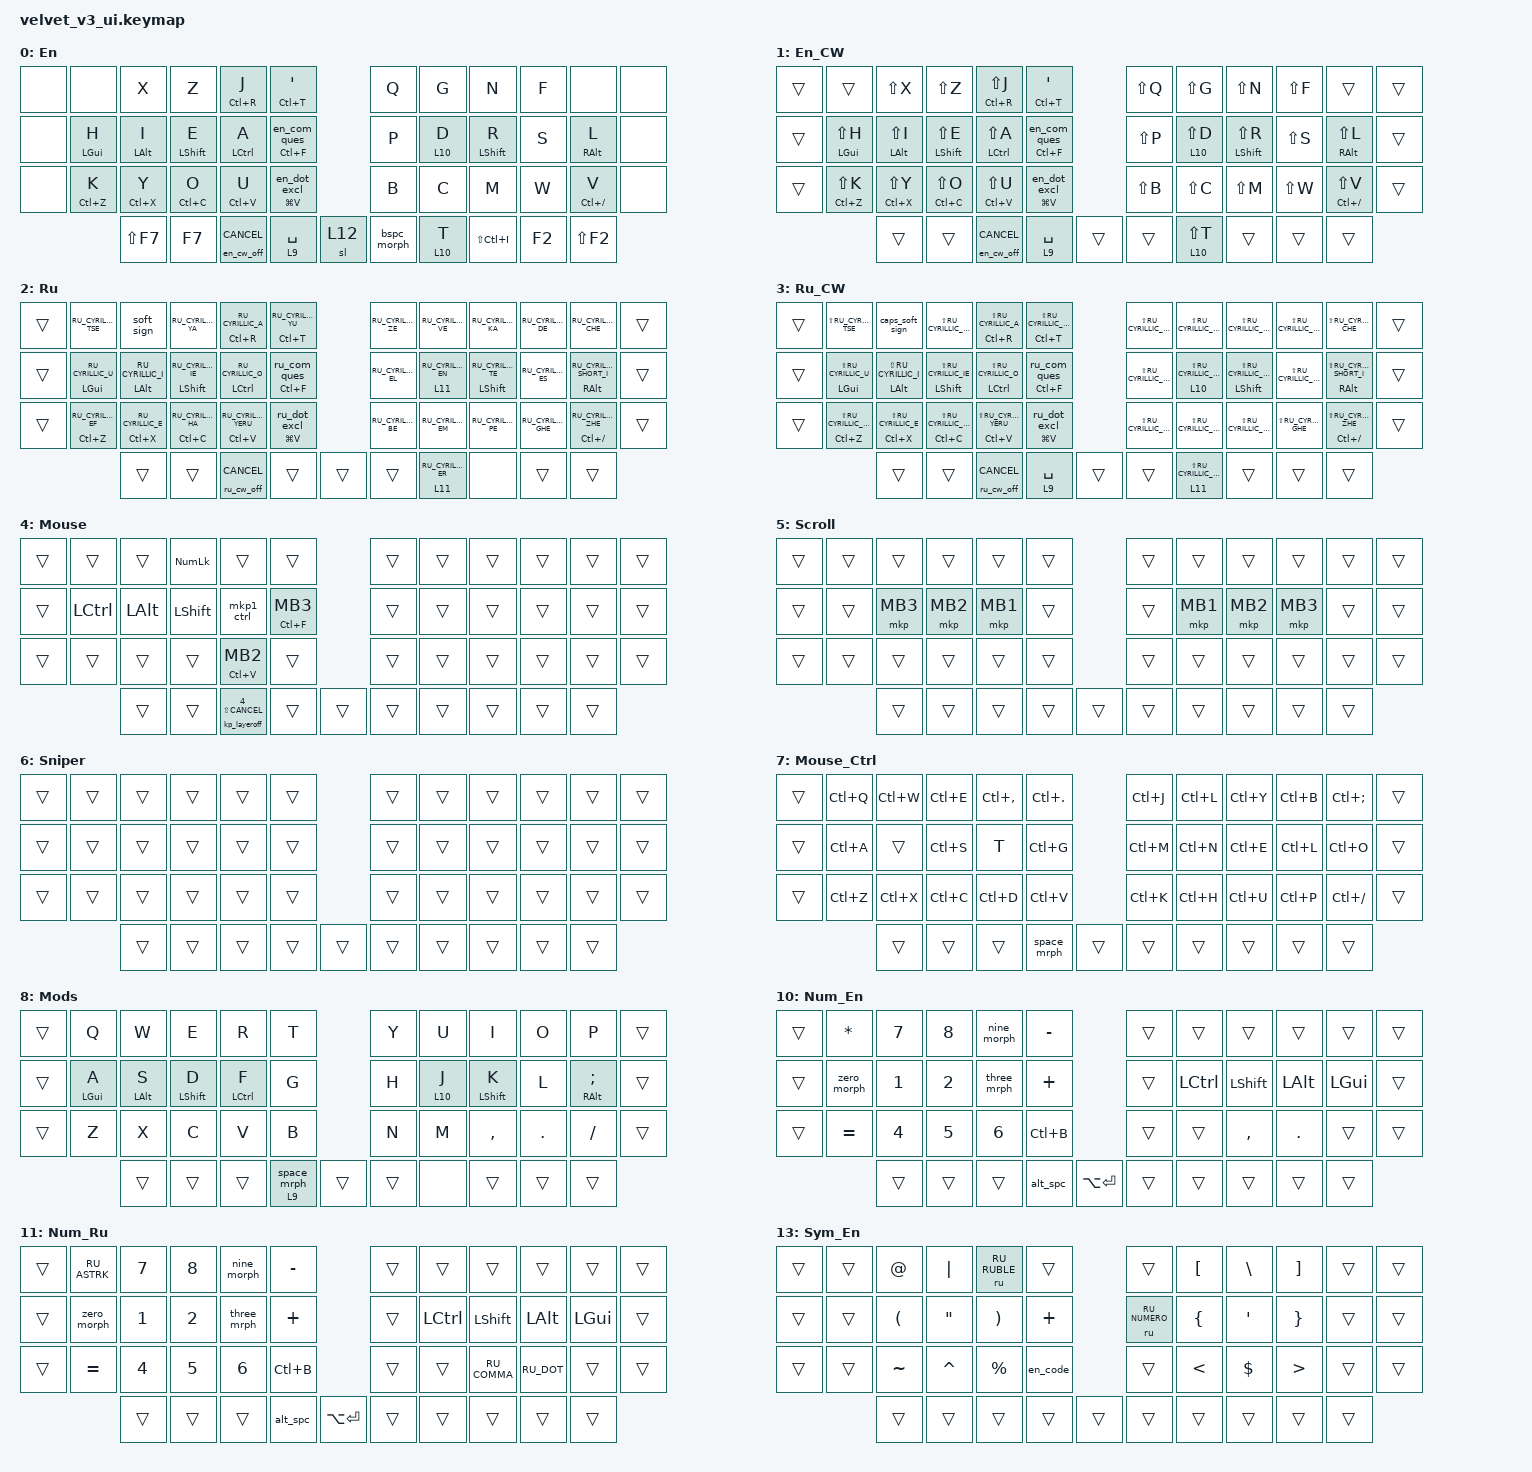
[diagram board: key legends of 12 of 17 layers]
#include "keys_ru.h"
#include <dt-bindings/zmk/input_transform.h>
#include <input/processors.dtsi>
#include <zephyr/dt-bindings/input/input-event-codes.h>
#include <dt-bindings/zmk/behaviors.h>
#include <behaviors.dtsi>
#include <dt-bindings/zmk/bt.h>
#include <dt-bindings/zmk/keys.h>
#include <dt-bindings/zmk/outputs.h>
#include <dt-bindings/zmk/pointing.h>

&mt {
    flavor = "tap-preferred";
    tapping-term-ms = <200>;
    bindings = <&kp_>, <&kp>;
};

&lt { flavor = "balanced"; };

&sl {
    release-after-ms = <5000>;
    ignore-modifiers;
};

&sk {
    release-after-ms = <5000>;
    quick-release;
};

&key_repeat { usage-pages = <HID_USAGE_KEY HID_USAGE_CONSUMER>; };

/ {
    combos {
        compatible = "zmk,combos";

        combo_ctrl_ent {
            bindings = <&kp LC(ENTER)>;
            key-positions = <2 4>;
            require-prior-idle-ms = <30>;
        };

        combo_enter {
            bindings = <&kp ENTER>;
            key-positions = <3 2>;
            require-prior-idle-ms = <30>;
            timeout-ms = <30>;
        };

        combo_tab {
            bindings = <&kp TAB>;
            key-positions = <14 15>;
            require-prior-idle-ms = <30>;
            timeout-ms = <30>;
        };

        combo_esc {
            bindings = <&kp ESC>;
            key-positions = <26 27>;
            require-prior-idle-ms = <30>;
            timeout-ms = <30>;
        };

        combo_ru {
            bindings = <&layer_ru>;
            key-positions = <27 28>;
            timeout-ms = <30>;
            require-prior-idle-ms = <(-1)>;
        };

        combo_en {
            bindings = <&layer_en>;
            key-positions = <31 32>;
            timeout-ms = <30>;
            require-prior-idle-ms = <(-1)>;
        };

        combo_osl_sym_en {
            bindings = <&sl 13>;
            key-positions = <19 20>;
            require-prior-idle-ms = <50>;
            layers = <0 1 13>;
        };

        combo_quotes_en {
            bindings = <&quotes_en>;
            require-prior-idle-ms = <30>;
            key-positions = <31 33>;
            layers = <0 1 13>;
        };

        combo_osl_sym_ru {
            bindings = <&sl 14>;
            key-positions = <19 20>;
            require-prior-idle-ms = <50>;
            layers = <2 3 14>;
        };

        combo_quotes_ru {
            bindings = <&quotes_ru>;
            key-positions = <31 33>;
            require-prior-idle-ms = <30>;
            layers = <2 3>;
        };

        combo_braces_en {
            bindings = <&braces_en>;
            key-positions = <19 21>;
            require-prior-idle-ms = <50>;
            layers = <0 1 13>;
        };

        cmb_bcsp {
            bindings = <&none>;
            timeout-ms = <30>;
            key-positions = <20 21>;
            require-prior-idle-ms = <15>;
            layers = <16>;
        };

        combo_she_ru {
            bindings = <&kp RU_CYRILLIC_SHA>;
            timeout-ms = <30>;
            key-positions = <32 33>;
            require-prior-idle-ms = <15>;
            layers = <2>;
        };

        combo_scha_ru {
            bindings = <&kp RU_CYRILLIC_SHCHA>;
            timeout-ms = <30>;
            key-positions = <8 9>;
            require-prior-idle-ms = <15>;
            layers = <2>;
        };

        combo_she_cw {
            bindings = <&kp LS(RU_CYRILLIC_SHA)>;
            timeout-ms = <30>;
            key-positions = <32 33>;
            layers = <3>;
            require-prior-idle-ms = <15>;
        };

        combo_scha_cw {
            bindings = <&kp LS(RU_CYRILLIC_SHCHA)>;
            timeout-ms = <30>;
            key-positions = <8 9>;
            layers = <3>;
            require-prior-idle-ms = <15>;
        };

        combo_capsword_en {
            bindings = <&to 1>;
            key-positions = <14 13>;
            layers = <0 1>;
        };

        combo_osl_fn {
            bindings = <&sl 15>;
            key-positions = <26 28>;
        };

        combo_osl_os {
            bindings = <&sl 16>;
            key-positions = <25 26>;
        };

        combo_capsword_ru {
            bindings = <&to 3>;
            key-positions = <14 13>;
            layers = <2 3>;
        };

        combo_yo_ru {
            bindings = <&kp RU_CYRILLIC_IO>;
            key-positions = <21 22>;
            layers = <2>;
        };

        combo_yo_cw_ru {
            bindings = <&kp LS(RU_CYRILLIC_IO)>;
            key-positions = <21 22>;
            layers = <3>;
        };

        combo_yo_en {
            bindings = <&ru RU_CYRILLIC_IO>;
            key-positions = <21 22>;
            layers = <0>;
        };

        parentheses {
            bindings = <&parentheses>;
            key-positions = <14 16>;
            timeout-ms = <30>;
            require-prior-idle-ms = <50>;
        };

        combo_braces_ru {
            bindings = <&braces_ru>;
            key-positions = <19 21>;
            timeout-ms = <25>;
            layers = <2 3 14>;
            require-prior-idle-ms = <50>;
        };

        combo_brackets_en {
            bindings = <&brackets_en>;
            key-positions = <7 9>;
            layers = <0 1 13>;
            timeout-ms = <30>;
            require-prior-idle-ms = <30>;
        };

        combo_brackets_ru {
            bindings = <&brackets_ru>;
            key-positions = <7 9>;
            layers = <2 3 14>;
            timeout-ms = <30>;
        };

        combo_minus {
            bindings = <&kp MINUS>;
            key-positions = <3 4>;
            require-prior-idle-ms = <30>;
            timeout-ms = <30>;
        };

        combo_grave_ru {
            bindings = <&ru_grave>;
            key-positions = <19 18>;
            layers = <2 3 14>;
        };

        combo_grave_en {
            bindings = <&en_grave>;
            key-positions = <19 18>;
            layers = <0 1 13>;
        };

        combo_under_en {
            bindings = <&kp UNDER>;
            key-positions = <7 8>;
            require-prior-idle-ms = <30>;
            timeout-ms = <30>;
        };

        combo_ru_hash {
            bindings = <&en HASH>;
            key-positions = <30 31>;
            layers = <2 3 14>;
        };

        combo_en_hash {
            bindings = <&kp HASH>;
            key-positions = <30 31>;
            layers = <0 1 13>;
        };

        combo_en_slash {
            bindings = <&kp SLASH>;
            key-positions = <16 17>;
            layers = <0 1 10 13>;
        };

        combo_ru_slash {
            bindings = <&en SLASH>;
            key-positions = <16 17>;
            layers = <2 3 14 11>;
        };

        combo_en_amp {
            bindings = <&kp AMPS>;
            key-positions = <28 29>;
            layers = <0 1 10 13>;
        };

        combo_en_semi {
            bindings = <&kp SEMI>;
            key-positions = <4 5>;
            layers = <0 1 10 13>;
        };

        combo_ru_semi {
            bindings = <&kp RU_SEMI>;
            key-positions = <4 5>;
            layers = <2 3 11 14>;
        };

        combo_ru_amp {
            bindings = <&en AMPS>;
            key-positions = <28 29>;
            layers = <2 3 11 14>;
        };

        combo_en_colon {
            bindings = <&kp COLON>;
            key-positions = <6 7>;
            layers = <0 1 10 13>;
        };

        combo_ru_colon {
            bindings = <&kp RU_COLON>;
            key-positions = <6 7>;
            layers = <2 3 10 13>;
        };
    };

    macros {
        layer_ru: lg_ru {
            compatible = "zmk,behavior-macro";
            #binding-cells = <0>;
            bindings = <&to 2 &kp LS(LC(N8))>;
            label = "LG_RU";
            tap-ms = <40>;
            wait-ms = <0>;
        };

        layer_en: lg_en {
            compatible = "zmk,behavior-macro";
            #binding-cells = <0>;
            bindings = <&to 0 &kp LS(LC(N9))>;
            label = "LG_EN";
            tap-ms = <40>;
            wait-ms = <0>;
        };

        to_ru: to_ru {
            compatible = "zmk,behavior-macro";
            #binding-cells = <0>;
            bindings = <&kp LC(LS(N8))>;
            label = "TO_RU";
            tap-ms = <40>;
            wait-ms = <0>;
        };

        to_en: to_en {
            compatible = "zmk,behavior-macro";
            #binding-cells = <0>;
            bindings = <&kp LC(LS(N9))>;
            label = "TO_EN";
            wait-ms = <0>;
            tap-ms = <40>;
        };

        en: en {
            compatible = "zmk,behavior-macro-one-param";
            #binding-cells = <1>;
            bindings = <&kp LC(LS(N9)) &macro_param_1to1 &kp MACRO_PLACEHOLDER &kp LC(LS(N8))>;
            label = "EN";
            wait-ms = <10>;
            tap-ms = <40>;
        };

        ru: ru {
            compatible = "zmk,behavior-macro-one-param";
            #binding-cells = <1>;
            bindings = <&kp LC(LS(N8)) &macro_param_1to1 &kp MACRO_PLACEHOLDER &kp LS(LC(N9))>;
            label = "RU";
            tap-ms = <40>;
        };

        alt_tab: alt_tab {
            compatible = "zmk,behavior-macro";
            #binding-cells = <0>;
            bindings =
                <&macro_wait_time 30>,
                <&macro_press>,
                <&kp LEFT_ALT>,
                <&macro_tap>,
                <&kp TAB>,
                <&macro_release>,
                <&kp LEFT_ALT>;

            label = "ALT_TAB";
            tap-ms = <30>;
        };

        select_row: select_row {
            compatible = "zmk,behavior-macro";
            #binding-cells = <0>;
            bindings = <&kp END &kp LS(HOME)>;
            label = "SELECT_ROW";
            wait-ms = <0>;
        };

        en_code: en_code_block {
            compatible = "zmk,behavior-macro";
            #binding-cells = <0>;
            bindings =
                <&macro_wait_time 10>,
                <&kp GRAVE &kp GRAVE &kp GRAVE &kp RETURN &kp RET &kp GRAVE &kp GRAVE &kp GRAVE &kp UP_ARROW>;

            label = "EN_CODE_BLOCK";
        };

        ru_code: ru_code {
            compatible = "zmk,behavior-macro";
            #binding-cells = <0>;
            bindings = <&kp LS(LC(N9)) &kp GRAVE &kp GRAVE &kp GRAVE &kp RETURN &kp RET &kp GRAVE &kp GRAVE &kp GRAVE &kp UP_ARROW &kp LC(LS(N8))>;
            label = "RU_CODE";
            tap-ms = <30>;
        };

        ru_cw_off: ru_cw_off {
            compatible = "zmk,behavior-macro-one-param";
            #binding-cells = <1>;
            bindings = <&macro_param_1to1 &kp MACRO_PLACEHOLDER &to 2>;
            label = "RU_CW_OFF";
            wait-ms = <0>;
        };

        en_cw_off: en_cw_off {
            compatible = "zmk,behavior-macro-one-param";
            #binding-cells = <1>;
            bindings = <&macro_param_1to1 &kp MACRO_PLACEHOLDER &to 0>;
            label = "EN_CW_OFF";
            wait-ms = <0>;
        };

        zeros_macro: zeros_macro {
            compatible = "zmk,behavior-macro";
            #binding-cells = <0>;
            bindings = <&kp N0 &kp N0 &kp N0 &kp N0 &kp N0 &kp N0>;
            label = "ZEROS_MACRO";
            tap-ms = <200>;
        };

        osm_ctrl_shift: osm_ctrl_shift {
            compatible = "zmk,behavior-macro";
            #binding-cells = <0>;
            bindings = <&sk LS(LCTRL) &sl 8>;
            label = "OSM_CTRL_SHIFT";
            wait-ms = <0>;
            tap-ms = <0>;
        };

        ml: ml {
            compatible = "zmk,behavior-macro-one-param";
            #binding-cells = <1>;
            bindings =
                <&macro_param_1to1 &key_on MACRO_PLACEHOLDER &layer_on 8>,
                <&macro_pause_for_release>,
                <&macro_param_1to1 &key_off MACRO_PLACEHOLDER &layer_off 8>;

            label = "Mod Layer";
            wait-ms = <0>;
            tap-ms = <0>;
        };

        quotes_ru: dbl_quote {
            compatible = "zmk,behavior-macro";
            #binding-cells = <0>;
            bindings = <&kp LS(NUMBER_2) &kp LS(NUMBER_2) &kp LEFT_ARROW>;
            label = "DBL_QUOTE";
            wait-ms = <0>;
        };

        quotes_en: quotes_en {
            compatible = "zmk,behavior-macro";
            #binding-cells = <0>;
            bindings = <&kp DOUBLE_QUOTES &kp DOUBLE_QUOTES &kp LEFT_ARROW>;
            label = "QUOTES_EN";
            wait-ms = <0>;
        };

        braces_en: braces_en {
            compatible = "zmk,behavior-macro";
            #binding-cells = <0>;
            bindings = <&kp LEFT_BRACE &kp RIGHT_BRACE &kp LEFT>;
            label = "BRACES_EN";
            wait-ms = <0>;
        };

        braces_ru: braces_ru {
            compatible = "zmk,behavior-macro";
            #binding-cells = <0>;
            bindings = <&to_en &braces_en &to_ru>;
            label = "BRACES_RU";
            wait-ms = <0>;
            tap-ms = <40>;
        };

        brackets_en: brackets_en {
            compatible = "zmk,behavior-macro";
            #binding-cells = <0>;
            bindings = <&kp LEFT_BRACKET &kp RIGHT_BRACKET &kp LEFT_ARROW>;
            label = "BRACKETS_EN";
            wait-ms = <0>;
        };

        brackets_ru: brackets_ru {
            compatible = "zmk,behavior-macro";
            #binding-cells = <0>;
            bindings = <&to_en &brackets_en &to_ru>;
            label = "BRACKETS_RU";
            wait-ms = <20>;
            tap-ms = <40>;
        };

        parentheses: parentheses {
            compatible = "zmk,behavior-macro";
            #binding-cells = <0>;
            bindings = <&kp LEFT_PARENTHESIS &kp RIGHT_PARENTHESIS &kp LEFT_ARROW>;
            label = "PARENTHESES";
            wait-ms = <0>;
        };

        less_greater_en: less_greater_en {
            compatible = "zmk,behavior-macro";
            #binding-cells = <0>;
            bindings = <&kp LESS_THAN &kp GREATER_THAN &kp LEFT>;
            label = "LESS_GREATER_EN";
            wait-ms = <0>;
        };

        less_greater_ru: less_greater_ru {
            compatible = "zmk,behavior-macro";
            #binding-cells = <0>;
            bindings = <&kp LS(LC(N9)) &less_greater_en &kp LS(LC(N8))>;
            label = "LESS_GREATER_RU";
        };

        osm_ctrl: osm_ctrl {
            compatible = "zmk,behavior-macro";
            #binding-cells = <0>;
            bindings = <&sk LCTRL &sl 8>;
            label = "OSM_CTRL";
            wait-ms = <0>;
            tap-ms = <0>;
        };

        sync_lg: sync_lg {
            compatible = "zmk,behavior-macro";
            #binding-cells = <0>;
            bindings = <&tog 2>;
            label = "SYNC_LG";
        };

        alt_spc: alt_spc {
            compatible = "zmk,behavior-macro";
            #binding-cells = <0>;
            bindings = <&kp LA(SPACE) &layer_off 4>;
            label = "ALT_SPC";
            wait-ms = <0>;
            tap-ms = <0>;
        };

        bspc_msoff: bspc_msoff {
            compatible = "zmk,behavior-macro";
            #binding-cells = <0>;
            bindings = <&layer_off 4 &bspc_morph>;
            label = "BSPC_MSOFF";
            tap-ms = <0>;
            wait-ms = <0>;
        };

        trns_msoff: trns_msoff {
            compatible = "zmk,behavior-macro";
            #binding-cells = <0>;
            bindings =
                <&macro_press>,
                <&trans>,
                <&macro_pause_for_release>,
                <&macro_release>,
                <&trans>,
                <&macro_tap>,
                <&layer_off 4>;

            label = "TRNS_MSOFF";
            wait-ms = <0>;
            tap-ms = <0>;
        };

        kp_msoff: kp_msoff {
            compatible = "zmk,behavior-macro-one-param";
            #binding-cells = <1>;
            bindings =
                <&macro_tap>,
                <&layer_off 4>,
                <&macro_press>,
                <&macro_param_1to1 &kp MACRO_PLACEHOLDER>,
                <&macro_pause_for_release>,
                <&macro_release>,
                <&macro_param_1to1 &kp MACRO_PLACEHOLDER>;

            label = "KP_MSOFF";
            wait-ms = <0>;
            tap-ms = <0>;
        };

        kp_layeroff: cancel_msoff {
            compatible = "zmk,behavior-macro-two-param";
            #binding-cells = <2>;
            bindings = <&macro_param_1to1 &layer_off MACRO_PLACEHOLDER &macro_param_2to1 &kp MACRO_PLACEHOLDER>;
            label = "CANCEL_MSOFF";
        };

        mkp1_ctrl: mkp1_ctrl {
            compatible = "zmk,behavior-macro";
            #binding-cells = <0>;
            bindings =
                <&macro_press>,
                <&mkp MB1 &mo 7 &kp LCTRL>,
                <&macro_pause_for_release>,
                <&macro_release>,
                <&mo 7>,
                <&macro_wait_time 50>,
                <&kp LCTRL &mkp MB1>;

            label = "MKP1_CTRL";
            wait-ms = <0>;
            tap-ms = <0>;
        };

        dkp: dkp {
            compatible = "zmk,behavior-macro-two-param";
            #binding-cells = <2>;
            bindings =
                <&macro_press>,
                <&macro_param_1to1 &kp MACRO_PLACEHOLDER &macro_param_2to1 &kp MACRO_PLACEHOLDER>,
                <&macro_pause_for_release>,
                <&macro_release>,
                <&macro_param_1to1 &kp MACRO_PLACEHOLDER &macro_param_2to1 &kp MACRO_PLACEHOLDER>;

            label = "DKP";
            wait-ms = <0>;
            tap-ms = <0>;
        };

        osm_shift: osm_shift {
            compatible = "zmk,behavior-macro";
            #binding-cells = <0>;
            bindings = <&sk LEFT_SHIFT &sl 8>;
            label = "OSM_SHIFT";
            wait-ms = <0>;
            tap-ms = <0>;
        };

        dbl_tap: dbl_tap {
            compatible = "zmk,behavior-macro-one-param";
            #binding-cells = <1>;
            bindings = <&macro_param_1to1 &kp MACRO_PLACEHOLDER &macro_param_1to1 &kp MACRO_PLACEHOLDER>;
            label = "DBL_TAP";
            tap-ms = <50>;
            wait-ms = <20>;
        };

        select_word: select_word {
            compatible = "zmk,behavior-macro";
            #binding-cells = <0>;
            bindings = <&kp LC(LEFT) &kp LC(LS(RIGHT))>;
            label = "SELECT_WORD";
        };

        kp_: kp_ {
            compatible = "zmk,behavior-macro-one-param";
            #binding-cells = <1>;
            bindings =
                <&macro_press>,
                <&macro_param_1to1 &kp MACRO_PLACEHOLDER>,
                <&macro_pause_for_release>,
                <&macro_release>,
                <&macro_param_1to1 &kp MACRO_PLACEHOLDER>;

            label = "KP_";
        };

        multi_kp: multi_kp {
            compatible = "zmk,behavior-macro-one-param";
            #binding-cells = <1>;
            bindings = <&macro_param_1to1 &kp MACRO_PLACEHOLDER &macro_param_1to1 &kp MACRO_PLACEHOLDER>;
            label = "MULTI_KP";
            tap-ms = <200>;
        };

        dbl_grave_ru: dbl_grave_ru {
            compatible = "zmk,behavior-macro";
            #binding-cells = <0>;
            bindings = <&kp LS(LC(N9)) &kp GRAVE &kp GRAVE &kp LEFT_ARROW &kp LS(LC(N8))>;
            label = "DBL_GRAVE_RU";
            wait-ms = <0>;
            tap-ms = <30>;
        };

        dbl_grave_en: dbl_grave_en {
            compatible = "zmk,behavior-macro";
            #binding-cells = <0>;
            bindings = <&kp GRAVE &kp GRAVE &kp LEFT_ARROW>;
            label = "DBL_GRAVE_EN";
            wait-ms = <0>;
            tap-ms = <30>;
        };

        triple_press: triple_press {
            compatible = "zmk,behavior-macro-one-param";
            #binding-cells = <1>;
            bindings = <&macro_param_1to1 &kp MACRO_PLACEHOLDER &macro_param_1to1 &kp MACRO_PLACEHOLDER &macro_param_1to1 &kp MACRO_PLACEHOLDER>;
            label = "TRIPLE_PRESS";
        };

        triple_press_en: triple_press_en {
            compatible = "zmk,behavior-macro-one-param";
            #binding-cells = <1>;
            bindings = <&kp N9 &macro_param_1to1 &kp MACRO_PLACEHOLDER &macro_param_1to1 &kp MACRO_PLACEHOLDER &macro_param_1to1 &kp MACRO_PLACEHOLDER &kp LS(LC(N8))>;
            label = "TRIPLE_PRESS_EN";
        };

        testops: testops {
            compatible = "zmk,behavior-macro";
            #binding-cells = <0>;
            bindings = <&kp LS(LC(LG(F7))) &kp LS(LC(LG(F8)))>;
            label = "TESTOPS";
            wait-ms = <500>;
            tap-ms = <150>;
        };
    };

    behaviors {
        en_magic: en_magic {
            compatible = "zmk,behavior-antecedent-morph";
            label = "EN_MAGIC";
            #binding-cells = <0>;
            defaults = <&none>;
            bindings = <&kp C>, <&kp B>, <&kp O>, <&kp E>, <&kp E>, <&kp I>;

            antecedents = <S I Z Y U P>;
            max-delay-ms = <2000>;
        };

        ru_magic: ru_magic {
            compatible = "zmk,behavior-antecedent-morph";
            label = "RU_MAGIC";
            #binding-cells = <0>;
            defaults = <&none>;
            bindings = <&kp C>, <&kp O>;

            antecedents = <S Z>;
            max-delay-ms = <1500>;
        };

        layer_off: layer_off {
            compatible = "zmk,behavior-toggle-layer";
            label = "LAYER_OFF";
            #binding-cells = <1>;
            toggle-mode = "off";
        };

        hrm: hrm {
            compatible = "zmk,behavior-hold-tap";
            label = "Home Row Mod";
            bindings = <&kp>, <&kp>;

            #binding-cells = <2>;
            tapping-term-ms = <200>;
            flavor = "balanced";
        };

        hrm_slow: hrm_slow {
            compatible = "zmk,behavior-hold-tap";
            label = "HRM for slow fingers";
            bindings = <&kp>, <&kp>;

            #binding-cells = <2>;
            flavor = "tap-preferred";
            tapping-term-ms = <200>;
        };

        ru_lt_cw_off: ru_lt_cw_off {
            compatible = "zmk,behavior-hold-tap";
            label = "RU_LT_CW_OFF";
            bindings = <&mo>, <&ru_cw_off>;

            #binding-cells = <2>;
            tapping-term-ms = <180>;
            flavor = "balanced";
        };

        en_lt_cw_off: en_lt_cw_off {
            compatible = "zmk,behavior-hold-tap";
            label = "EN_LT_CW_OFF";
            bindings = <&mo>, <&en_cw_off>;

            #binding-cells = <2>;
            tapping-term-ms = <180>;
            flavor = "balanced";
        };

        hrl: hrl {
            compatible = "zmk,behavior-hold-tap";
            label = "Home Row Layer";
            bindings = <&mo>, <&kp>;

            #binding-cells = <2>;
            tapping-term-ms = <200>;
            flavor = "balanced";
        };

        lt_bspc: lt_bspc {
            compatible = "zmk,behavior-hold-tap";
            label = "LT with quick tap and mod morph";
            bindings = <&mo>, <&bspc_msoff>;

            #binding-cells = <2>;
            quick-tap-ms = <180>;
            tapping-term-ms = <180>;
            flavor = "balanced";
        };

        bspc_morph: bspc_morph {
            compatible = "zmk,behavior-mod-morph";
            label = "BSPC_MORPH";
            bindings = <&kp BACKSPACE>, <&kp DELETE>;

            #binding-cells = <0>;
            mods = <(MOD_LSFT)>;
        };

        key_on: key_on {
            compatible = "zmk,behavior-key-toggle";
            label = "KEY_ON";
            #binding-cells = <1>;
        };

        key_off: key_off {
            compatible = "zmk,behavior-key-toggle";
            label = "KEY_OFF";
            #binding-cells = <1>;
            toggle-mode = "off";
        };

        hrml: hrml {
            compatible = "zmk,behavior-hold-tap";
            label = "Home Row Mod Layer";
            bindings = <&ml>, <&kp>;

            #binding-cells = <2>;
            tapping-term-ms = <200>;
            flavor = "balanced";
        };

        layer_on: layer_on {
            compatible = "zmk,behavior-toggle-layer";
            label = "LAYER_ON";
            #binding-cells = <1>;
            toggle-mode = "on";
        };

        hrml_slow: hrml_slow {
            compatible = "zmk,behavior-hold-tap";
            label = "HRML for slow fingers";
            bindings = <&ml>, <&kp>;

            #binding-cells = <2>;
            tapping-term-ms = <200>;
            flavor = "tap-preferred";
        };

        soft_sign: soft_sign {
            compatible = "zmk,behavior-mod-morph";
            label = "SOFT_SIGN";
            bindings = <&kp M>, <&kp RIGHT_BRACKET>;

            #binding-cells = <0>;
            mods = <(MOD_LSFT)>;
        };

        en_dot_excl: en_dot_excl {
            compatible = "zmk,behavior-mod-morph";
            label = "EN_DOT_EXCL";
            bindings = <&en_cw_off DOT>, <&en_cw_off EXCL>;

            #binding-cells = <0>;
            mods = <(MOD_LSFT)>;
        };

        en_com_ques: en_com_ques {
            compatible = "zmk,behavior-mod-morph";
            label = "EN_COM_QUES";
            bindings = <&en_cw_off COMMA>, <&en_cw_off QUESTION>;

            #binding-cells = <0>;
            mods = <(MOD_LSFT)>;
        };

        ru_dot_excl: ru_dot_excl {
            compatible = "zmk,behavior-mod-morph";
            label = "RU_DOT_EXCL";
            bindings = <&ru_cw_off RU_DOT>, <&ru_cw_off EXCL>;

            #binding-cells = <0>;
            mods = <(MOD_LSFT)>;
        };

        ru_com_ques: ru_com_ques {
            compatible = "zmk,behavior-mod-morph";
            label = "RU_COM_QUES";
            bindings = <&ru_cw_off RU_COMMA>, <&ru_cw_off RU_QUESTION>;

            #binding-cells = <0>;
            mods = <(MOD_LSFT)>;
        };

        mkp_hold: mkp_hold {
            compatible = "zmk,behavior-hold-tap";
            label = "MKP_HOLD";
            bindings = <&kp>, <&mkp>;

            #binding-cells = <2>;
            tapping-term-ms = <200>;
            flavor = "tap-preferred";
        };

        trns_msoff_hold: trns_msoff_hold {
            compatible = "zmk,behavior-hold-tap";
            label = "TRNS_MSOFF_HOLD";
            bindings = <&kp>, <&trns_msoff>;

            #binding-cells = <2>;
            tapping-term-ms = <200>;
            flavor = "tap-preferred";
        };

        mkp_hold_msoff: mkp_hold_msoff {
            compatible = "zmk,behavior-hold-tap";
            label = "MKP_HOLD_MSOFF";
            bindings = <&kp_msoff>, <&mkp>;

            #binding-cells = <2>;
            tapping-term-ms = <200>;
            flavor = "tap-preferred";
        };

        trans_msoff_lr_hold: trans_msoff_lr_hold {
            compatible = "zmk,behavior-hold-tap";
            label = "TRANS_MSOFF_LR_HOLD";
            bindings = <&mo>, <&trns_msoff>;

            #binding-cells = <2>;
            tapping-term-ms = <200>;
            flavor = "balanced";
        };

        ru_dot_mt: ru_dot_mt {
            compatible = "zmk,behavior-hold-tap";
            label = "RU_DOT_MT";
            bindings = <&kp>, <&ru_dot_excl>;

            #binding-cells = <2>;
            tapping-term-ms = <200>;
            flavor = "tap-preferred";
        };

        ru_com_mt: ru_com_mt {
            compatible = "zmk,behavior-hold-tap";
            label = "RU_COM_MT";
            bindings = <&kp>, <&ru_com_ques>;

            #binding-cells = <2>;
            tapping-term-ms = <200>;
            flavor = "tap-preferred";
        };

        en_com_mt: en_com_mt {
            compatible = "zmk,behavior-hold-tap";
            label = "EN_COM_MT";
            bindings = <&kp>, <&en_com_ques>;

            #binding-cells = <2>;
            tapping-term-ms = <200>;
            flavor = "balanced";
        };

        en_dot_mt: en_dot_mt {
            compatible = "zmk,behavior-hold-tap";
            label = "EN_DOT_MT";
            bindings = <&kp>, <&en_dot_excl>;

            #binding-cells = <2>;
            tapping-term-ms = <200>;
            flavor = "balanced";
        };

        space_mrph: space_mrph {
            compatible = "zmk,behavior-mod-morph";
            label = "SPACE_MRPH";
            bindings = <&kp SPACE>, <&kp TAB>;

            #binding-cells = <0>;
            mods = <(MOD_LSFT|MOD_RSFT|MOD_LCTL|MOD_RCTL)>;
            keep-mods = <(MOD_LSFT|MOD_RSFT|MOD_LCTL|MOD_RCTL)>;
        };

        nine_morph: nine_morph {
            compatible = "zmk,behavior-mod-morph";
            label = "NINE_MORPH";
            bindings = <&kp N9>, <&kp LS(LC(R))>;

            #binding-cells = <0>;
            mods = <(MOD_LSFT)>;
        };

        hrs: hrs {
            compatible = "zmk,behavior-hold-tap";
            label = "HRS";
            bindings = <&kp>, <&kp>;

            #binding-cells = <2>;
            tapping-term-ms = <200>;
            flavor = "balanced";
            require-prior-idle-ms = <(-1)>;
        };

        ru_grave: ru_grave {
            compatible = "zmk,behavior-tap-dance";
            label = "RU_GRAVE";
            #binding-cells = <0>;
            bindings = <&en GRAVE>, <&dbl_grave_ru>, <&triple_press_en GRAVE>;

            tapping-term-ms = <180>;
        };

        en_grave: en_grave {
            compatible = "zmk,behavior-tap-dance";
            label = "EN_GRAVE";
            #binding-cells = <0>;
            bindings = <&kp GRAVE>, <&dbl_grave_en>, <&triple_press GRAVE>;

            tapping-term-ms = <180>;
        };

        caps_soft_sign: caps_soft_sign {
            compatible = "zmk,behavior-mod-morph";
            label = "CAPS_SOFT_SIGN";
            bindings =
                <&kp LS(RU_CYRILLIC_SOFT_SIGN)>,
                <&kp LS(RU_CYRILLIC_HARD_SIGN)>;

            #binding-cells = <0>;
            mods = <(MOD_LSFT)>;
        };

        three_mrph: three_mrph {
            compatible = "zmk,behavior-mod-morph";
            label = "THREE_MRPH";
            bindings = <&kp NUMBER_3>, <&kp LS(LC(F))>;

            #binding-cells = <0>;
            mods = <(MOD_LSFT)>;
        };

        space_lt: space_lt {
            compatible = "zmk,behavior-hold-tap";
            label = "SPACE_LT";
            bindings = <&mo>, <&space_mrph>;

            #binding-cells = <2>;
            tapping-term-ms = <200>;
            flavor = "balanced";
        };

        en_caps: en_caps {
            compatible = "zmk,behavior-tap-dance";
            label = "EN_CAPS";
            #binding-cells = <0>;
            bindings = <&to 1>, <&kp CAPSLOCK>;
        };

        ru_caps: ru_caps {
            compatible = "zmk,behavior-tap-dance";
            label = "RU_CAPS";
            #binding-cells = <0>;
            bindings = <&to 3>, <&kp CAPSLOCK>;
        };

        ctrl: ctrl {
            compatible = "zmk,behavior-hold-tap";
            label = "CTRL";
            bindings = <&kp>, <&ctrl_td>;

            #binding-cells = <2>;
            tapping-term-ms = <200>;
            flavor = "balanced";
        };

        ctrl_td: ctrl_td {
            compatible = "zmk,behavior-tap-dance";
            label = "CTRL_TD";
            #binding-cells = <0>;
            bindings = <&kp LCTRL>, <&dbl_tap LEFT_GUI>;
        };

        td_esc: td_esc {
            compatible = "zmk,behavior-tap-dance";
            label = "TD_ESC";
            #binding-cells = <0>;
            bindings = <&kp ESC>, <&kp LS(ESC)>;
        };

        mod_dtap: mod_dtap {
            compatible = "zmk,behavior-hold-tap";
            label = "MOD_DTAP";
            bindings = <&kp>, <&dbl_tap>;

            #binding-cells = <2>;
            tapping-term-ms = <200>;
            flavor = "balanced";
        };

        tops_cmd_x: tops_cmd_x {
            compatible = "zmk,behavior-hold-tap";
            label = "TOPS_CMD_X";
            bindings = <&kp>, <&testops>;

            #binding-cells = <2>;
            tapping-term-ms = <200>;
            flavor = "tap-preferred";
        };

        zero_morph: zero_morph {
            compatible = "zmk,behavior-mod-morph";
            label = "ZERO_MORPH";
            bindings = <&kp N0>, <&kp LS(LC(A))>;

            #binding-cells = <0>;
            mods = <(MOD_LCTL|MOD_LSFT)>;
        };

        mouse_layer: mouse_layer {
            compatible = "zmk,behavior-sticky-key";
            label = "MOUSE_LAYER";
            bindings = <&mo>;
            #binding-cells = <1>;
            release-after-ms = <200>;
        };

        zip_auto_mouse: zip_auto_mouse {
            compatible = "zmk,input-processor-temp-layer";
            #input-processor-cells = <2>;
            require-prior-idle-ms = <800>;
            excluded-positions = <>;
        };
    };

    keymap {
        compatible = "zmk,keymap";

        En {
            bindings = <
&none  &none                  &kp X                  &kp Z              &mt LC(R) J          &mt LC(T) APOS                             &kp Q     &kp G          &kp N              &kp F       &none              &none
&none  &hrml_slow LEFT_GUI H  &hrml_slow LEFT_ALT I  &hrs LEFT_SHIFT E  &hrml LCTRL A        &en_com_mt LC(F) 0                         &kp P     &hrl 10 D      &hrs LEFT_SHIFT R  &kp S       &hrml_slow RALT L  &none
&none  &mt LC(Z) K            &mt LC(X) Y            &mt LC(C) O        &mt LC(V) U          &en_dot_mt LG(V) 0                         &kp B     &kp C          &kp M              &kp W       &mt LC(SLASH) V    &none
                              &kp LS(F7)             &kp F7             &en_cw_off K_CANCEL  &lt 9 SPACE         &sl 12    &bspc_morph  &lt 10 T  &kp LS(LC(I))  &kp F2             &kp LS(F2)
            >;

            display-name = "En";
        };

        En_CW {
            bindings = <
&trans  &trans                     &kp LS(X)                  &kp LS(Z)              &mt LC(R) LS(J)      &mt LC(T) APOS                           &kp LS(Q)     &kp LS(G)      &kp LS(N)              &kp LS(F)  &trans                 &trans
&trans  &hrml_slow LEFT_GUI LS(H)  &hrml_slow LEFT_ALT LS(I)  &hrs LEFT_SHIFT LS(E)  &hrml LCTRL LS(A)    &en_com_mt LC(F) 0                       &kp LS(P)     &hrl 10 LS(D)  &hrs LEFT_SHIFT LS(R)  &kp LS(S)  &hrml_slow RALT LS(L)  &trans
&trans  &mt LC(Z) LS(K)            &mt LC(X) LS(Y)            &mt LC(C) LS(O)        &mt LC(V) LS(U)      &en_dot_mt LG(V) 0                       &kp LS(B)     &kp LS(C)      &kp LS(M)              &kp LS(W)  &mt LC(SLASH) LS(V)    &trans
                                   &trans                     &trans                 &en_cw_off K_CANCEL  &en_lt_cw_off 9 SPACE  &trans    &trans  &lt 10 LS(T)  &trans         &trans                 &trans
            >;

            display-name = "En_CW";
        };

        Ru {
            bindings = <
&trans  &kp RU_CYRILLIC_TSE                &soft_sign                         &kp RU_CYRILLIC_YA              &mt LC(R) RU_CYRILLIC_A     &mt LC(T) RU_CYRILLIC_YU                    &kp RU_CYRILLIC_ZE     &kp RU_CYRILLIC_VE      &kp RU_CYRILLIC_KA              &kp RU_CYRILLIC_DE   &kp RU_CYRILLIC_CHE                  &trans
&trans  &hrml_slow LEFT_GUI RU_CYRILLIC_U  &hrml_slow LEFT_ALT RU_CYRILLIC_I  &hrs LEFT_SHIFT RU_CYRILLIC_IE  &hrml LCTRL RU_CYRILLIC_O   &ru_com_mt LC(F) 0                          &kp RU_CYRILLIC_EL     &hrl 11 RU_CYRILLIC_EN  &hrs LEFT_SHIFT RU_CYRILLIC_TE  &kp RU_CYRILLIC_ES   &hrml_slow RALT RU_CYRILLIC_SHORT_I  &trans
&trans  &mt LC(Z) RU_CYRILLIC_EF           &mt LC(X) RU_CYRILLIC_E            &mt LC(C) RU_CYRILLIC_HA        &mt LC(V) RU_CYRILLIC_YERU  &ru_dot_mt LG(V) 0                          &kp RU_CYRILLIC_BE     &kp RU_CYRILLIC_EM      &kp RU_CYRILLIC_PE              &kp RU_CYRILLIC_GHE  &mt LC(SLASH) RU_CYRILLIC_ZHE        &trans
                                           &trans                             &trans                          &ru_cw_off K_CANCEL         &trans                    &trans    &trans  &lt 11 RU_CYRILLIC_ER  &none                   &trans                          &trans
            >;

            display-name = "Ru";
        };

        Ru_CW {
            bindings = <
&trans  &kp LS(RU_CYRILLIC_TSE)                &caps_soft_sign                        &kp LS(RU_CYRILLIC_YA)              &mt LC(R) LS(RU_CYRILLIC_A)     &mt LC(T) LS(RU_CYRILLIC_YU)                    &kp LS(RU_CYRILLIC_ZE)     &kp LS(RU_CYRILLIC_VE)      &kp LS(RU_CYRILLIC_KA)              &kp LS(RU_CYRILLIC_DE)   &kp LS(RU_CYRILLIC_CHE)                  &trans
&trans  &hrml_slow LEFT_GUI LS(RU_CYRILLIC_U)  &hrml_slow LEFT_ALT LS(RU_CYRILLIC_I)  &hrs LEFT_SHIFT LS(RU_CYRILLIC_IE)  &hrml LCTRL LS(RU_CYRILLIC_O)   &ru_com_mt LC(F) 0                              &kp LS(RU_CYRILLIC_EL)     &hrl 10 LS(RU_CYRILLIC_EN)  &hrs LEFT_SHIFT LS(RU_CYRILLIC_TE)  &kp LS(RU_CYRILLIC_ES)   &hrml_slow RALT LS(RU_CYRILLIC_SHORT_I)  &trans
&trans  &mt LC(Z) LS(RU_CYRILLIC_EF)           &mt LC(X) LS(RU_CYRILLIC_E)            &mt LC(C) LS(RU_CYRILLIC_HA)        &mt LC(V) LS(RU_CYRILLIC_YERU)  &ru_dot_mt LG(V) 0                              &kp LS(RU_CYRILLIC_BE)     &kp LS(RU_CYRILLIC_EM)      &kp LS(RU_CYRILLIC_PE)              &kp LS(RU_CYRILLIC_GHE)  &mt LC(SLASH) LS(RU_CYRILLIC_ZHE)        &trans
                                               &trans                                 &trans                              &ru_cw_off K_CANCEL             &ru_lt_cw_off 9 SPACE         &trans    &trans  &lt 11 LS(RU_CYRILLIC_ER)  &trans                      &trans                              &trans
            >;

            display-name = "Ru_CW";
        };

        Mouse {
            bindings = <
&trans  &trans     &trans        &kp KP_NUMLOCK  &trans                       &trans                                       &trans  &trans  &trans  &trans  &trans  &trans
&trans  &kp LCTRL  &kp LEFT_ALT  &kp LSHFT       &mkp1_ctrl                   &mkp_hold_msoff LC(F) MB3                    &trans  &trans  &trans  &trans  &trans  &trans
&trans  &trans     &trans        &trans          &mkp_hold LC(V) MB2          &trans                                       &trans  &trans  &trans  &trans  &trans  &trans
                   &trans        &trans          &kp_layeroff 4 LS(K_CANCEL)  &trans                     &trans    &trans  &trans  &trans  &trans  &trans
            >;

            display-name = "Mouse";
        };

        Scroll {
            bindings = <
&trans  &trans  &trans    &trans    &trans    &trans                    &trans  &trans    &trans    &trans    &trans  &trans
&trans  &trans  &mkp MB3  &mkp MB2  &mkp MB1  &trans                    &trans  &mkp MB1  &mkp MB2  &mkp MB3  &trans  &trans
&trans  &trans  &trans    &trans    &trans    &trans                    &trans  &trans    &trans    &trans    &trans  &trans
                &trans    &trans    &trans    &trans  &trans    &trans  &trans  &trans    &trans    &trans
            >;

            display-name = "Scroll";
        };

        Sniper {
            bindings = <
&trans  &trans  &trans  &trans  &trans  &trans                    &trans  &trans  &trans  &trans  &trans  &trans
&trans  &trans  &trans  &trans  &trans  &trans                    &trans  &trans  &trans  &trans  &trans  &trans
&trans  &trans  &trans  &trans  &trans  &trans                    &trans  &trans  &trans  &trans  &trans  &trans
                &trans  &trans  &trans  &trans  &trans    &trans  &trans  &trans  &trans  &trans
            >;

            display-name = "Sniper";
        };

        Mouse_Ctrl {
            bindings = <
&trans  &kp LC(Q)  &kp LC(W)  &kp LC(E)  &kp LC(COMMA)  &kp LC(DOT)                    &kp LC(J)  &kp LC(L)  &kp LC(Y)  &kp LC(B)  &kp LC(SEMI)   &trans
&trans  &kp LC(A)  &trans     &kp LC(S)  &kp T          &kp LC(G)                      &kp LC(M)  &kp LC(N)  &kp LC(E)  &kp LC(L)  &kp LC(O)      &trans
&trans  &kp LC(Z)  &kp LC(X)  &kp LC(C)  &kp LC(D)      &kp LC(V)                      &kp LC(K)  &kp LC(H)  &kp LC(U)  &kp LC(P)  &kp LC(SLASH)  &trans
                   &trans     &trans     &trans         &space_mrph  &trans    &trans  &trans     &trans     &trans     &trans
            >;

            display-name = "Mouse_Ctrl";
        };

        Mods {
            bindings = <
&trans  &kp Q             &kp W             &kp E              &kp R         &kp T                            &kp Y  &kp U      &kp I              &kp O    &kp P                &trans
&trans  &hrm_slow LGUI A  &hrm_slow LALT S  &hrm LEFT_SHIFT D  &hrm LCTRL F  &kp G                            &kp H  &hrl 10 J  &hrm LEFT_SHIFT K  &kp L    &hrm_slow RALT SEMI  &trans
&trans  &kp Z             &kp X             &kp C              &kp V         &kp B                            &kp N  &kp M      &kp COMMA          &kp DOT  &kp SLASH            &trans
                          &trans            &trans             &trans        &space_lt 9 0  &trans    &trans  &none  &trans     &trans             &trans
            >;

            display-name = "Mods";
        };

        Nav {
            bindings = <
&trans  &trans                          &kp LA(LC(GRAVE))                &kp LC(LS(LA(LG(TAB))))  &kp LS(LC(LA(LG(F1))))    &testops                                     &trans        &kp HOME   &kp UP    &kp END    &kp DELETE   &trans
&trans  &hrm LEFT_GUI LC(LEFT_BRACKET)  &hrm LALT LC(RIGHT_BRACKET)      &kp LSHFT                &mod_dtap LCTRL LEFT_GUI  &zeros_macro                                 &select_word  &kp LEFT   &kp DOWN  &kp RIGHT  &select_row  &trans
&trans  &mt LC(Z) LG(LS(LEFT_BRACKET))  &mt LC(X) LG(LS(RIGHT_BRACKET))  &mt LC(C) LS(F6)         &mt LC(V) LS(LC(LA(V)))   &kp LS(LG(LC(F9)))                           &kp CAPS      &kp PG_UP  &none     &kp PG_DN  &trans       &trans
                                        &trans                           &trans                   &trans                    &alt_spc            &kp LA(ENTER)    &trans  &trans        &trans     &trans    &trans
            >;

            display-name = "Nav";
        };

        Num_En {
            bindings = <
&trans  &kp ASTERISK  &kp NUMBER_7  &kp NUMBER_8  &nine_morph  &kp MINUS                           &trans  &trans     &trans      &trans        &trans        &trans
&trans  &zero_morph   &kp N1        &kp N2        &three_mrph  &kp PLUS                            &trans  &kp LCTRL  &kp LSHIFT  &kp LEFT_ALT  &kp LEFT_GUI  &trans
&trans  &kp EQUAL     &kp N4        &kp N5        &kp N6       &kp LC(B)                           &trans  &trans     &kp COMMA   &kp DOT       &trans        &trans
                      &trans        &trans        &trans       &alt_spc   &kp LA(ENTER)    &trans  &trans  &trans     &trans      &trans
            >;

            display-name = "Num_En";
        };

        Num_Ru {
            bindings = <
&trans  &kp RU_ASTRK  &kp NUMBER_7  &kp NUMBER_8  &nine_morph  &kp MINUS                           &trans  &trans     &trans        &trans        &trans        &trans
&trans  &zero_morph   &kp N1        &kp N2        &three_mrph  &kp PLUS                            &trans  &kp LCTRL  &kp LSHIFT    &kp LEFT_ALT  &kp LEFT_GUI  &trans
&trans  &kp EQUAL     &kp N4        &kp N5        &kp N6       &kp LC(B)                           &trans  &trans     &kp RU_COMMA  &kp RU_DOT    &trans        &trans
                      &trans        &trans        &trans       &alt_spc   &kp LA(ENTER)    &trans  &trans  &trans     &trans        &trans
            >;

            display-name = "Num_Ru";
        };

        App {
            bindings = <
&trans  &kp LA(LC(LS(P)))  &kp LS(LA(LC(W)))  &kp LS(LA(LC(E)))  &kp LS(LA(LC(R)))  &kp LS(LA(LC(T)))                    &kp LS(LA(LC(Y)))  &kp LS(LA(LC(U)))  &kp LS(LA(LC(I)))      &kp LS(LA(LC(O)))    &kp LS(LA(LC(P)))          &trans
&trans  &kp LS(LA(LC(A)))  &kp LS(LA(LC(S)))  &kp LS(LA(LC(D)))  &kp LS(LA(LC(F)))  &kp LS(LA(LC(G)))                    &kp LS(LA(LC(H)))  &kp LS(LA(LC(J)))  &kp LS(LA(LC(K)))      &kp LS(LA(LC(L)))    &kp LS(LA(LC(SEMICOLON)))  &trans
&trans  &kp LS(LC(LA(Z)))  &kp LS(LA(LC(X)))  &kp LS(LA(LC(C)))  &kp LS(LC(LG(V)))  &kp LS(LA(LC(B)))                    &kp LS(LA(LC(N)))  &kp LS(LC(LA(M)))  &kp LS(LA(LC(COMMA)))  &kp LS(LA(LC(DOT)))  &kp LS(LC(LA(SLASH)))      &trans
                           &trans             &trans             &layer_off 12      &none              &sl 12    &trans  &trans             &trans             &trans                 &trans
            >;

            display-name = "App";
        };

        Sym_En {
            bindings = <
&trans  &trans  &kp AT                &kp PIPE           &ru RU_RUBLE           &trans                      &trans         &kp LEFT_BRACKET  &kp BACKSLASH     &kp RIGHT_BRACKET  &trans  &trans
&trans  &trans  &kp LEFT_PARENTHESIS  &kp DOUBLE_QUOTES  &kp RIGHT_PARENTHESIS  &kp PLUS                    &ru RU_NUMERO  &kp LEFT_BRACE    &kp SINGLE_QUOTE  &kp RIGHT_BRACE    &trans  &trans
&trans  &trans  &kp TILDE             &kp CARET          &kp PERCENT            &en_code                    &trans         &kp LESS_THAN     &kp DOLLAR        &kp GREATER_THAN   &trans  &trans
                &trans                &trans             &trans                 &trans    &trans    &trans  &trans         &trans            &trans            &trans
            >;

            display-name = "Sym_En";
        };

        Sym_Ru {
            bindings = <
&trans  &trans  &en AT                &en PIPE              &kp RU_RUBLE  &trans                      &trans         &en LEFT_BRACKET  &en BACKSLASH     &en RIGHT_BRACKET  &trans  &trans
&trans  &trans  &kp LEFT_PARENTHESIS  &kp RU_DOUBLE_QUOTES  &kp RPAR      &kp PLUS                    &kp RU_NUMERO  &en LEFT_BRACE    &en SINGLE_QUOTE  &en RIGHT_BRACE    &trans  &trans
&trans  &trans  &en TILDE             &en CARET             &kp PERCENT   &ru_code                    &trans         &en LESS_THAN     &en DOLLAR        &en GREATER_THAN   &trans  &trans
                &trans                &trans                &trans        &trans    &trans    &trans  &trans         &trans            &trans            &trans
            >;

            display-name = "Sym_Ru";
        };

        Fn {
            bindings = <
&trans  &trans   &kp F7  &kp F8  &kp F9  &trans                     &trans  &trans     &trans          &trans    &trans        &trans
&trans  &kp F10  &kp F1  &kp F2  &kp F3  &kp F12                    &trans  &kp LCTRL  &kp LEFT_SHIFT  &kp LALT  &kp LEFT_GUI  &trans
&trans  &kp F11  &kp F4  &kp F5  &kp F6  &trans                     &trans  &trans     &trans          &trans    &trans        &trans
                 &trans  &trans  &trans  &trans   &trans    &trans  &trans  &trans     &trans          &trans
            >;

            display-name = "Fn";
        };

        OS {
            bindings = <
&trans  &bt BT_SEL 2  &trans         &kp LA(LC(N2))            &kp LC(LA(NUMBER_3))  &kp LC(LA(NUMBER_4))                    &trans        &studio_unlock  &trans  &trans  &bt BT_CLR  &trans
&trans  &bt BT_SEL 1  &kp LC(RIGHT)  &kp C_PLAY_PAUSE          &kp C_VOLUME_UP       &kp C_BRI_UP                            &out OUT_BLE  &kp F24         &trans  &trans  &soft_off   &trans
&trans  &bt BT_SEL 0  &none          &kp LC(LS(LEFT_BRACKET))  &kp C_VOL_DN          &kp C_BRI_DN                            &out OUT_USB  &kp F23         &trans  &trans  &trans      &trans
                      &trans         &trans                    &trans                &trans                &trans    &trans  &trans        &trans          &trans  &trans
            >;

            display-name = "OS";
        };
    };
};

&trackball { cpi = <0>; };
